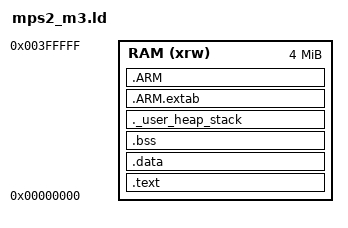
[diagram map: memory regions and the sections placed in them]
/*
 * FreeRTOS V202011.00
 * Copyright (C) 2020 Amazon.com, Inc. or its affiliates.  All Rights Reserved.
 *
 * Permission is hereby granted, free of charge, to any person obtaining a copy of
 * this software and associated documentation files (the "Software"), to deal in
 * the Software without restriction, including without limitation the rights to
 * use, copy, modify, merge, publish, distribute, sublicense, and/or sell copies of
 * the Software, and to permit persons to whom the Software is furnished to do so,
 * subject to the following conditions:
 *
 * The above copyright notice and this permission notice shall be included in all
 * copies or substantial portions of the Software.
 *
 * THE SOFTWARE IS PROVIDED "AS IS", WITHOUT WARRANTY OF ANY KIND, EXPRESS OR
 * IMPLIED, INCLUDING BUT NOT LIMITED TO THE WARRANTIES OF MERCHANTABILITY, FITNESS
 * FOR A PARTICULAR PURPOSE AND NONINFRINGEMENT. IN NO EVENT SHALL THE AUTHORS OR
 * COPYRIGHT HOLDERS BE LIABLE FOR ANY CLAIM, DAMAGES OR OTHER LIABILITY, WHETHER
 * IN AN ACTION OF CONTRACT, TORT OR OTHERWISE, ARISING FROM, OUT OF OR IN
 * CONNECTION WITH THE SOFTWARE OR THE USE OR OTHER DEALINGS IN THE SOFTWARE.
 *
 * https://www.FreeRTOS.org
 * https://www.gihub.com/FreeRTOS
 *
 */

MEMORY
{
    RAM (xrw)  : ORIGIN = 0x00000000,  LENGTH = 4M
}

_Min_Heap_Size = 0x200 ;        /* Required amount of heap. */
_Min_Stack_Size = 0x400 ;       /* Required amount of stack. */

_estack = ORIGIN(RAM) + LENGTH(RAM);

SECTIONS
{
    .text : {
        . = ALIGN(4);
        KEEP(*(.isr_vector))
        *(.text*)
        KEEP (*(.init))
        KEEP (*(.fini))
        . = ALIGN(4);
        _etext = .;
        _sidata = _etext;
    } > RAM

    .data : AT ( _sidata )
    {
        . = ALIGN(4);
        _sdata = .;
        *(.data*)
        *(.rodata*)
        KEEP(*(.eh_frame))
        . = ALIGN(4);
        _edata = .;
    } >RAM

    .bss :
    {
        . = ALIGN(4);
        _sbss = .;
        __bss_start__ = _sbss;
        *(.bss*)
        *(COMMON)
        . = ALIGN(4);
        _ebss = .;
        __bss_end__ = _ebss;
    } >RAM

    ._user_heap_stack :
    {
        . = ALIGN(8);
        PROVIDE ( end = . );
        PROVIDE ( _end = . );
        _heap_bottom = .;
        . = . + _Min_Heap_Size;
        _heap_top = .;
        . = . + _Min_Stack_Size;
        . = ALIGN(8);
       } >RAM

	.ARM.extab :
	{
		. = ALIGN(4);
		*(.ARM.extab* .gnu.linkonce.armextab.*)
		. = ALIGN(4);
	} >RAM

	.ARM :
	{
		. = ALIGN(4);
		__exidx_start = .;
		*(.ARM.exidx*)
		__exidx_end = .;
		. = ALIGN(4);
	} >RAM
}

